# Spirit3 register map
File version: 1.0
CPU: CM0+ r0p0, little endian, no MPU, no FPU, 2 interrupt priority bits
Registers are 32-bit, read-write, reset 0x0 unless marked. A register's access mark holds for its fields unless they carry their own. Offsets are from the block's base; [hi:lo] are bit positions; {n}, {i} and the like mark numbered series.

## MR_SUBG
Base 0x49000000
0x00 RF_FSM0_TIMEOUT reset 0x14
  [7:0] ENA_RFREG_TIMER — Timeout for the RF regulator startup (duration in ENA_RF_REG state) Step = 16/CLK16M=1us
0x04 RF_FSM1_TIMEOUT reset 0x6
  [7:0] SYNTH_SETUP_TIMER — Timeout management for the RF regulator to stabilize after PLL power on Step = 16/CLK16M=1us
0x08 RF_FSM2_TIMEOUT reset 0x50
  [7:0] VCO_CALIB_LOCK_TIMER — Timeout for the PLL calibration + PLL lock (duration of CALIB_VCO+LOCKRXTX states) Step = 16/CLK16M=1us
0x0C RF_FSM3_TIMEOUT reset 0x28
  [7:0] VCO_LOCK_TIMER — Timeout for the PLL lock event when no calibration is requested (duration in LOCKRXTX state) Step = 16/CLK16M=1us
0x10 RF_FSM4_TIMEOUT reset 0xF
  [7:0] EN_RX_TIMER — Timeout for the analog RX chain setup with PGA precharge active (duration in EN_RX state) Step = 16/CLK16M=1us
0x14 RF_FSM5_TIMEOUT reset 0x19
  [7:0] EN_PA_TIMER — Timeout for the PA setup (duration in EN_PA state) Step = 16/CLK16M=1us
0x18 RF_FSM6_TIMEOUT reset 0x19
  [7:0] PA_DWN_ANA_TIMER — Timeout for the analog PA (DAC) ramp down (duration in PA_DWN_ANA state) Step = 16/CLK16M=1us
0x1C RF_FSM7_TIMEOUT reset 0x5
  [7:0] EN_LNA_TIMER — Timeout for RX chain last signals settlement once PGA precharge is shut down (duration in EN_LNA state)
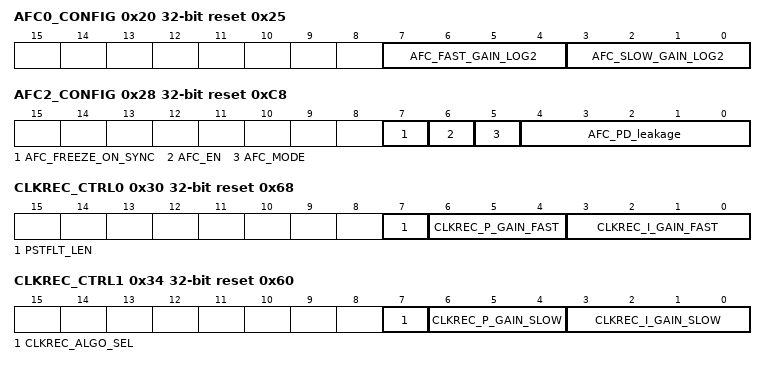
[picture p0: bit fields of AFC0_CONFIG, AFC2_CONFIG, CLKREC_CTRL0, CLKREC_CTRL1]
0x20 AFC0_CONFIG reset 0x25
  [7:4] AFC_FAST_GAIN_LOG2 — AFC loop gain in fast mode (2's log)
  [3:0] AFC_SLOW_GAIN_LOG2 — AFC loop gain in slow mode (2's log)
0x24 AFC1_CONFIG reset 0x18
  [7:0] AFC_FAST_PERIOD — Length of the AFC fast period (in number of samples unit)
0x28 AFC2_CONFIG reset 0xC8
  [7] AFC_FREEZE_ON_SYNC — Freeze the AFC correction upon SYNC word detection
  [6] AFC_EN — Enable AFC
  [5] AFC_MODE — Select AFC mode
  [4:0] AFC_PD_leakage — AFC Peak Detection leakage
0x2C AFC3_CONFIG
  [0] AFC_INIT_MODE — Control the initialization phase of the AGC and clock recovery algorithms
0x30 CLKREC_CTRL0 reset 0x68
  [7] PSTFLT_LEN — Control the length of the demodulator post-filter
  [6:4] CLKREC_P_GAIN_FAST — Clock recovery fast loop gain (log2)
  [3:0] CLKREC_I_GAIN_FAST — Integral fast gain for the clock recovery loop (PLL mode only)
0x34 CLKREC_CTRL1 reset 0x60
  [7] CLKREC_ALGO_SEL — Symbol timing recovery algorithm selection
  [6:4] CLKREC_P_GAIN_SLOW — Clock recovery slow loop gain (log2)
  [3:0] CLKREC_I_GAIN_SLOW — Integral slow gain for the clock recovery loop (PLL mode only)
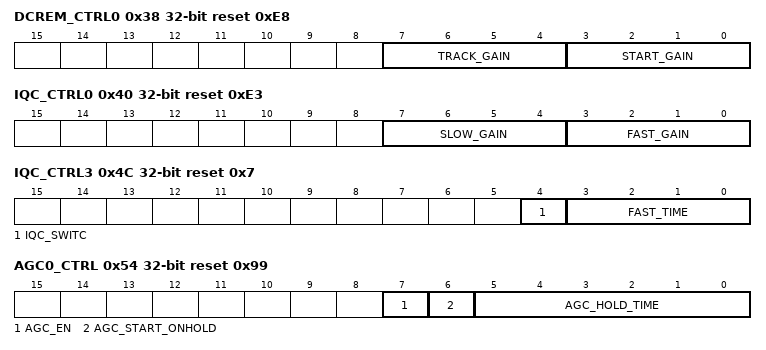
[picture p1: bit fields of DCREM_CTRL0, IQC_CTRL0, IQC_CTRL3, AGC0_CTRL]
0x38 DCREM_CTRL0 reset 0xE8
  [7:4] TRACK_GAIN — Filter gain in track mode for the DC removal block
  [3:0] START_GAIN — Filter gain in start mode for the DC removal block
0x3C DCREM_CTRL1 reset 0x5
  [3:0] LN2TIME2SET — Set the length of the start period for the DC removal block
0x40 IQC_CTRL0 reset 0xE3
  [7:4] SLOW_GAIN — Gain of the correction loop in slow mode
  [3:0] FAST_GAIN — Gain of the correction loop in fast mode
0x44 IQC_CTRL1 reset 0x8
  [7:0] QPD_ATTACK — Attack coefficient for QPD
0x48 IQC_CTRL2 reset 0x8
  [7:0] QPD_DECAY — Decay coefficient for QPD
0x4C IQC_CTRL3 reset 0x7
  [4] IQC_SWITC — (test and debug purpose only)
  [3:0] FAST_TIME — Duration of the fast mode
0x54 AGC0_CTRL reset 0x99
  [7] AGC_EN — Enable the AGC
  [6] AGC_START_ONHOLD — Start the AGC with a hold phase
  [5:0] AGC_HOLD_TIME
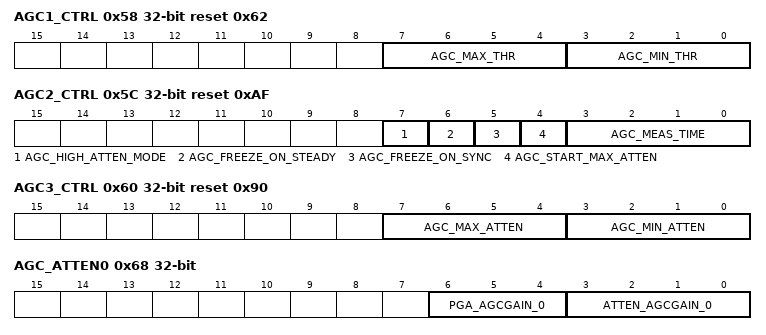
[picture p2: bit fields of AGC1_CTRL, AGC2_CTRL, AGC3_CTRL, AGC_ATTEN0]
0x58 AGC1_CTRL reset 0x62
  [7:4] AGC_MAX_THR — Maximum signal threshold
  [3:0] AGC_MIN_THR — Minimum signal threshold
0x5C AGC2_CTRL reset 0xAF
  [7] AGC_HIGH_ATTEN_MODE — Enable the high attenuation mode
  [6] AGC_FREEZE_ON_STEADY — Enable the autofreeze feature
  [5] AGC_FREEZE_ON_SYNC — Enable the freeze on SYNC detection feature
  [4] AGC_START_MAX_ATTEN — Start the AGC with maximum attenuation
  [3:0] AGC_MEAS_TIME — Measure time
0x60 AGC3_CTRL reset 0x90
  [7:4] AGC_MAX_ATTEN — Maximum AGC attenuation
  [3:0] AGC_MIN_ATTEN — Minimum AGC attenuation
0x64 AGC4_CTRL reset 0x2
  [3:0] AGC_FREEZE_THR — Signal threshold for the autofreeze feature
0x68 AGC_ATTEN0
  [6:4] PGA_AGCGAIN_0 — AGC attenuation control setting for step 0 on PGA point
  [3:0] ATTEN_AGCGAIN_0 — AGC attenuation control setting for step 0 for LNA+BOM point
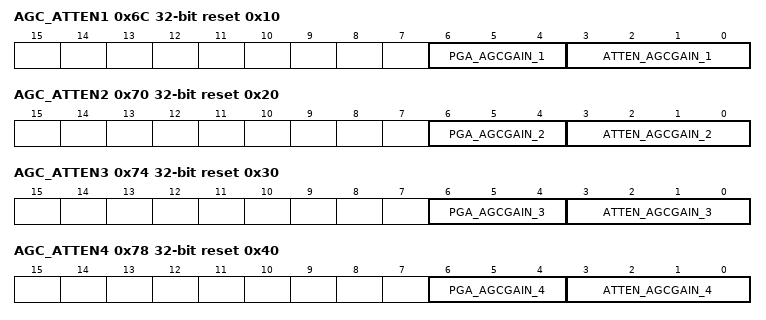
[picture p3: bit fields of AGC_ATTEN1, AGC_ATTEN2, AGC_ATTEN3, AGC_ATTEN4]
0x6C AGC_ATTEN1 reset 0x10
  [6:4] PGA_AGCGAIN_1 — AGC attenuation control setting for step 1 on PGA point
  [3:0] ATTEN_AGCGAIN_1 — AGC attenuation control setting for step 1 for LNA+BOM point
0x70 AGC_ATTEN2 reset 0x20
  [6:4] PGA_AGCGAIN_2 — AGC attenuation control setting for step 2 on PGA point
  [3:0] ATTEN_AGCGAIN_2 — AGC attenuation control setting for step 2 for LNA+BOM point
0x74 AGC_ATTEN3 reset 0x30
  [6:4] PGA_AGCGAIN_3 — AGC attenuation control setting for step 3 on PGA point
  [3:0] ATTEN_AGCGAIN_3 — AGC attenuation control setting for step 3 for LNA+BOM point
0x78 AGC_ATTEN4 reset 0x40
  [6:4] PGA_AGCGAIN_4 — AGC attenuation control setting for step 4 on PGA point
  [3:0] ATTEN_AGCGAIN_4 — AGC attenuation control setting for step 4 for LNA+BOM point
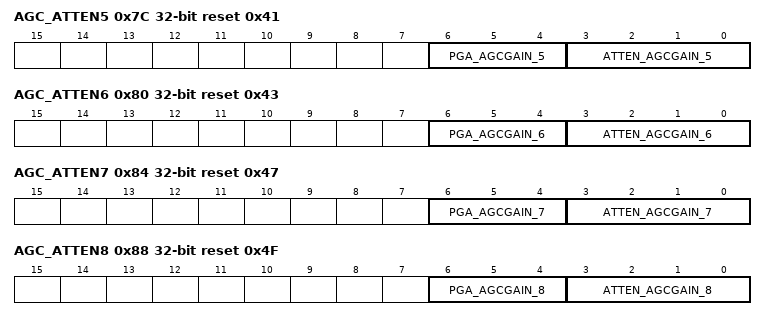
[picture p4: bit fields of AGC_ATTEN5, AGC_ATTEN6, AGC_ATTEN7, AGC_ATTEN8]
0x7C AGC_ATTEN5 reset 0x41
  [6:4] PGA_AGCGAIN_5 — AGC attenuation control setting for step 5 on PGA point
  [3:0] ATTEN_AGCGAIN_5 — AGC attenuation control setting for step 5 for LNA+BOM point
0x80 AGC_ATTEN6 reset 0x43
  [6:4] PGA_AGCGAIN_6 — AGC attenuation control setting for step 6 on PGA point
  [3:0] ATTEN_AGCGAIN_6 — AGC attenuation control setting for step 6 for LNA+BOM point
0x84 AGC_ATTEN7 reset 0x47
  [6:4] PGA_AGCGAIN_7 — AGC attenuation control setting for step 7 on PGA point
  [3:0] ATTEN_AGCGAIN_7 — AGC attenuation control setting for step 7 for LNA+BOM point
0x88 AGC_ATTEN8 reset 0x4F
  [6:4] PGA_AGCGAIN_8 — AGC attenuation control setting for step 8 on PGA point
  [3:0] ATTEN_AGCGAIN_8 — AGC attenuation control setting for step 8 for LNA+BOM point
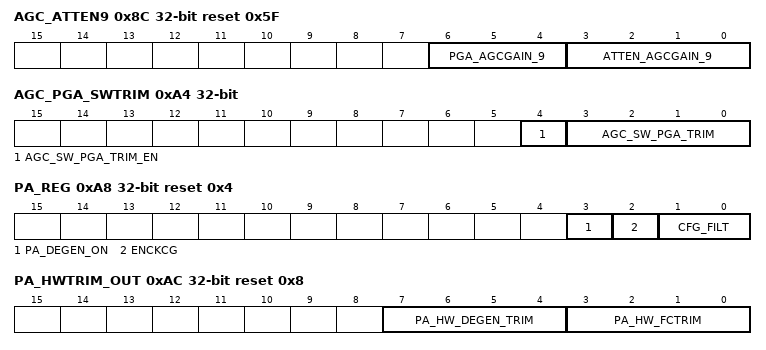
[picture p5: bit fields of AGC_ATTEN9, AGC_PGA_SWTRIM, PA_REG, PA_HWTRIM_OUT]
0x8C AGC_ATTEN9 reset 0x5F
  [6:4] PGA_AGCGAIN_9 — AGC attenuation control setting for step 9 on PGA point
  [3:0] ATTEN_AGCGAIN_9 — AGC attenuation control setting for step 9 for LNA+BOM point
{0x8C+4i} AGC{i}_ATTEN_TRIM reset 0xAF (i=1..4)
  [7:0] AGC{i}_ATTEN_TRIM_IN — AGC ATTEN trim[7:0] (calibration in) for step{i} on AGC_ATTEN
0xA0 AGC_PGA_HWTRIM_OUT ro reset 0x8
  [3:0] AGC_HW_PGA_TRIM — AGC PGA calibration information loaded by HW from the SoC flash (OBL section)
0xA4 AGC_PGA_SWTRIM
  [4] AGC_SW_PGA_TRIM_EN — Enable overload of PGA HW trim by a SW value
  [3:0] AGC_SW_PGA_TRIM — AGC PGA calibration information provided by SW
0xA8 PA_REG reset 0x4
  [3] PA_DEGEN_ON — Enable a 'degeneration' mode, which introduces a pre-distortion to linearize the power control curve
  [2] ENCKCG — FIR clock gating
  [1:0] CFG_FILT — FIR configuration
0xAC PA_HWTRIM_OUT ro reset 0x8
  [7:4] PA_HW_DEGEN_TRIM — MSB part meaning
  [3:0] PA_HW_FCTRIM — PA FC trimming information loaded by HW
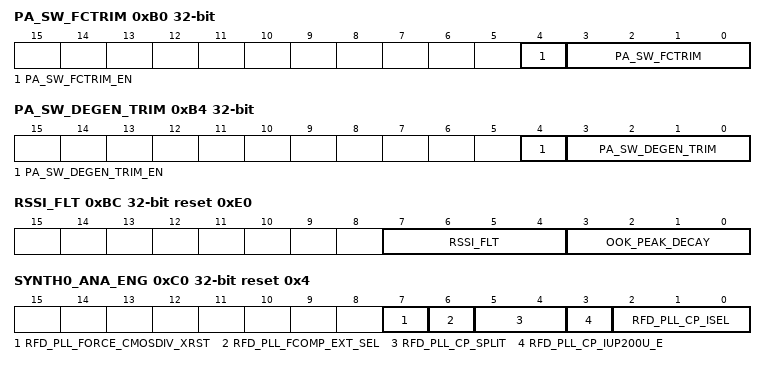
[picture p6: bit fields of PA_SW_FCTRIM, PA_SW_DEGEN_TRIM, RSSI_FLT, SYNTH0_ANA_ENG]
0xB0 PA_SW_FCTRIM
  [4] PA_SW_FCTRIM_EN — Enable overload of PA FC HW trim by a SW value
  [3:0] PA_SW_FCTRIM — PA FC trimming information provided by SW
0xB4 PA_SW_DEGEN_TRIM
  [4] PA_SW_DEGEN_TRIM_EN — Enable overload of PA DEGEN HW trim by a SW value
  [3:0] PA_SW_DEGEN_TRIM — PA DEGEN trimming information provided by SW
0xBC RSSI_FLT reset 0xE0
  [7:4] RSSI_FLT — Gain of the RSSI filter
  [3:0] OOK_PEAK_DECAY — Peak decay control for OOK
0xC0 SYNTH0_ANA_ENG reset 0x4
  [7] RFD_PLL_FORCE_CMOSDIV_XRST — For debug
  [6] RFD_PLL_FCOMP_EXT_SEL — For debug
  [5:4] RFD_PLL_CP_SPLIT — Change CP comparator current capability (for debug)
  [3] RFD_PLL_CP_IUP200U_E — For debug
  [2:0] RFD_PLL_CP_ISEL — Change Charge Pump biasing current configuration (for debug) default value is centered value = 3'b100
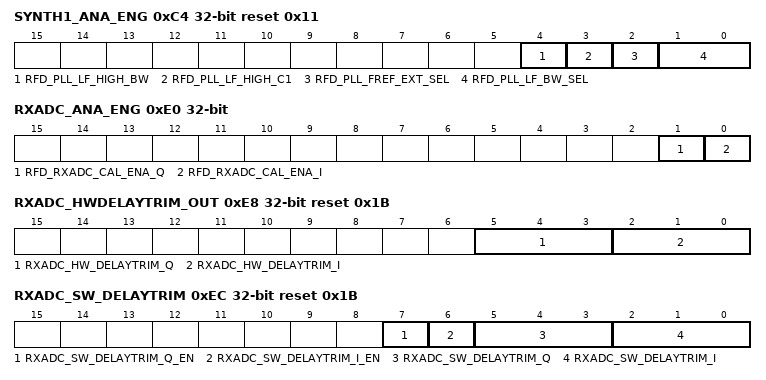
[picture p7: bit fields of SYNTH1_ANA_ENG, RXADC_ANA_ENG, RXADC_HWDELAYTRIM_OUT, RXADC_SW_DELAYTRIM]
0xC4 SYNTH1_ANA_ENG reset 0x11
  [4] RFD_PLL_LF_HIGH_BW — Double Resistor’s filter value (for debug) Default value (normal mode) is1
  [3] RFD_PLL_LF_HIGH_C1 — For debug. PLL-Loop Filter setting (=1 select the maximum value of C1 in loop filter)
  [2] RFD_PLL_FREF_EXT_SEL — For debug
  [1:0] RFD_PLL_LF_BW_SEL — Resistor filter’s bandwidth adjustment (for debug) Default value (normal mode) is 01
0xC8 SYNTH2_ANA_ENG reset 0x4
  [2:0] RFD_PLL_VCO_ALC_AMP — Select the level of max VCO amplitude in amplitude level control loop
0xD4 SYNTHCAL_DIG_ENG
  [7:0] PLL_RFCOUNTER_OFFSET — Control offset of PLL_RFCOUNTER output
0xE0 RXADC_ANA_ENG
  [1] RFD_RXADC_CAL_ENA_Q — Enable calibration on RX_ADC Q channel
  [0] RFD_RXADC_CAL_ENA_I — Enable calibration on RX_ADC I channel
0xE8 RXADC_HWDELAYTRIM_OUT ro reset 0x1B
  [5:3] RXADC_HW_DELAYTRIM_Q — Control bits of the RX ADC loop delay for Q channel
  [2:0] RXADC_HW_DELAYTRIM_I — Control bits of the RX ADC loop delay for I channel
0xEC RXADC_SW_DELAYTRIM reset 0x1B
  [7] RXADC_SW_DELAYTRIM_Q_EN — Select the SW trim instead of the HW trimmings
  [6] RXADC_SW_DELAYTRIM_I_EN — Select the SW trim instead of the HW trimmings
  [5:3] RXADC_SW_DELAYTRIM_Q — Control bits of the RX ADC loop delay for Q channel, provided by SW
  [2:0] RXADC_SW_DELAYTRIM_I — Control bits of the RX ADC loop delay for I channel, provided by SW
0xF4 RX_AAF_HWTRIM_OUT ro reset 0x6
  [3:0] AAF_HW_FCTRIM — AAF calibration information loaded by HW
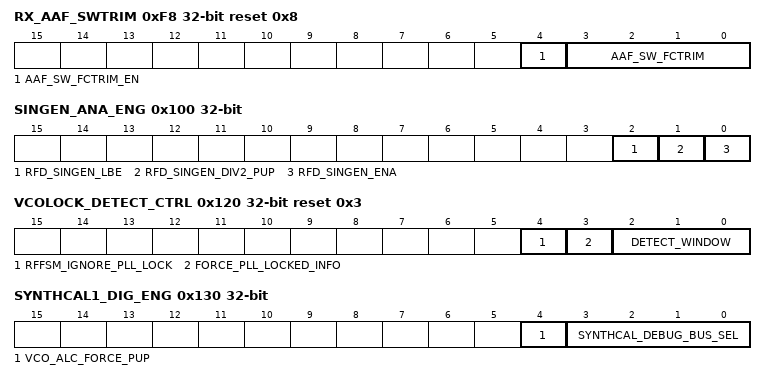
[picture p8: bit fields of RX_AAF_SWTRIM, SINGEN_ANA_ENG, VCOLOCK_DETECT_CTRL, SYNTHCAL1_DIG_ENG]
0xF8 RX_AAF_SWTRIM reset 0x8
  [4] AAF_SW_FCTRIM_EN — Select AAF_SW_TRIM[3:0] instead of AAF_HW_TRIM[3:0] info to provide to AAF analog block as calibration value
  [3:0] AAF_SW_FCTRIM — AAF calibration information to provide by SW (supposed to be the result of the AAF calibration, stored in a non-volatile memory)
0x100 SINGEN_ANA_ENG
  [2] RFD_SINGEN_LBE — This bit value is directly connected to the RFSUBG analog IP pin
  [1] RFD_SINGEN_DIV2_PUP — This bit value is directly connected to the RFSUBG analog IP pin
  [0] RFD_SINGEN_ENA — Enable SINGEN signal for the RFSUBG analog IP
0x104 RFANA_SPARE_IN_ENG
  [7:0] RFANA_SPARE_IN — Spare bits entering directly the RFSUBG analog IP
0x108 RFANA_SPARE_OUT ro
  [7:0] RFANA_SPARE_OUT — Spare bits coming directly from the RFSUBG analog IP
0x10C RFANA_PLL_SPARE_IN reset 0x80
  [7:4] RFANA_PLL_SPARE_IN — Spare bits entering directly the RFSUBG analog IP
0x120 VCOLOCK_DETECT_CTRL reset 0x3
  [4] RFFSM_IGNORE_PLL_LOCK — (debug and test) Information for the Radio FSM to go on sequence despite PLL is not locked
  [3] FORCE_PLL_LOCKED_INFO — (debug and test) Disable the PLL lock detection and force the PLL lock information high (for debug and test purposes) digital block
  [2:0] DETECT_WINDOW — Define integration window width for lock detection
0x124 RF_FSM8_TIMEOUT reset 0xA
  [7:0] SYNTH_PDWN_TIMER — Timeout management for the RF regulator to stabilize after PLL shut down
0x128 RF_FSM9_TIMEOUT reset 0x6
  [7:0] END_RX_TIMER — Timeout management for the RF regulator to stabilize after analog RX chain shut down
0x12C RF_FSM10_TIMEOUT reset 0x6
  [7:0] END_TX_TIMER — Timeout management for the RF regulator to stabilize after clock stop on the analog PA
0x130 SYNTHCAL1_DIG_ENG
  [4] VCO_ALC_FORCE_PUP — Force the enable of the Analog Amplitude Level Control on VCO (debug and test only)
  [3:0] SYNTHCAL_DEBUG_BUS_SEL — Select what is visible in DEBUG_BUS[7:0] in SYNTHCAL_DIG_OUT register
0x138 SYNTHCAL_DIG_OUT ro
  [7:0] SYNTHCAL_DEBUG_BUS — VCO calibration debug bus
0x140 DTB_CONFIG
  [5:0] DTB_CONFIG — DTB configuration selection.
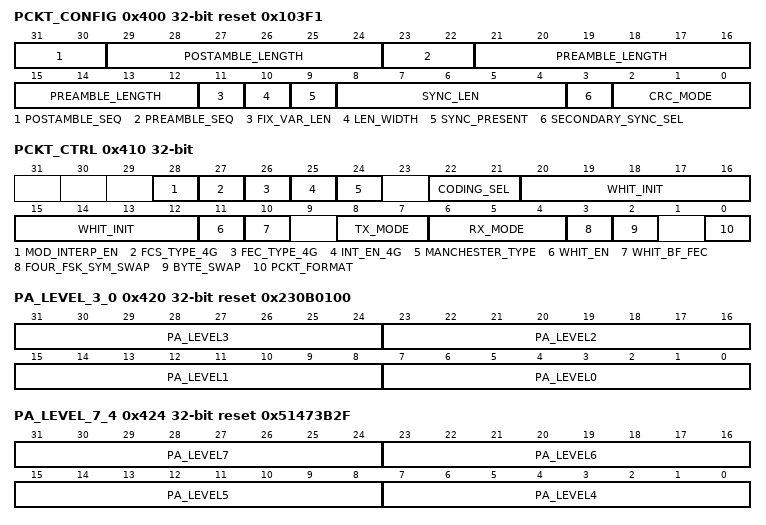
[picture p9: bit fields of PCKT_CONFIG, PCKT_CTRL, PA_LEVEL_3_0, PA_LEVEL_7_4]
0x400 PCKT_CONFIG reset 0x103F1
  [31:30] POSTAMBLE_SEQ — Packet postamble control: postamble bit sequence selection
  [29:24] POSTAMBLE_LENGTH — Length of the POSTAMBLE in pair of bits (0 to 126 bits)
  [23:22] PREAMBLE_SEQ — Select the PREAMBLE pattern to be applied
  [21:12] PREAMBLE_LENGTH — Length of the PREAMBLE in pairs of bits (0 to 2046 bits)
  [11] FIX_VAR_LEN — Select the length mode
  [10] LEN_WIDTH — Indicates if the LENGTH field is defined on 1 byte or 2 bytes
  [9] SYNC_PRESENT — Indicate if a SYNC word is present on the frame or not (null length)
  [8:4] SYNC_LEN — Length of the SYNC (and secondary) SYNC word in 1-bit granularity
  [3] SECONDARY_SYNC_SEL — In TX mode: this bit selects which synchro word is sent on the frame between SYNC and SEC_SYNC
  [2:0] CRC_MODE — CRC type (0, 8, 16, 16 802.15.4 compatible, 24, 32 bits)
0x404 SYNC reset 0x23232323
  [31:0] SYNC — Synchro word
0x408 SEC_SYNC
  [31:0] SEC_SYNC — Secondary Synchro word
0x40C CRC_INIT
  [31:0] CRC_INIT_VAL — CRC initialization value
0x410 PCKT_CTRL
  [28] MOD_INTERP_EN — Enable frequency interpolator (for 2-GFSK and 4-GFSK)
  [27] FCS_TYPE_4G — FCS type value in header field for 802.15.4g
  [26] FEC_TYPE_4G — FEC type for 802.15.4g
  [25] INT_EN_4G — This field is used as Interleaving enable for 802.15.4g
  [24] MANCHESTER_TYPE — Change the Manchester encoding polarity
  [22:21] CODING_SEL — Coding / decoding selection
  [20:12] WHIT_INIT — Whitening initialization value
  [11] WHIT_EN — Whitening enable
  [10] WHIT_BF_FEC — Whitening before FEC feature
  [8:7] TX_MODE
  [6:4] RX_MODE
  [3] FOUR_FSK_SYM_SWAP — Invert bit to symbol mapping for 4(G)FSK
  [2] BYTE_SWAP — (feature for Basic Packet format only)
  [0] PCKT_FORMAT — Packet format
0x414 DATABUFFER0_PTR
  [31:2] DATABUFFER0_PTR — Start address to be used by the Data Buffer0
0x418 DATABUFFER1_PTR
  [31:2] DATABUFFER1_PTR — Start address to be used by the Data Buffer1
0x41C DATABUFFER_SIZE
  [15:0] DATABUFFER_SIZE — Size of the Data Buffers (Data Buffer0 and Data Buffer1) expressed in byte unit
0x420 PA_LEVEL_3_0 reset 0x230B0100
  [31:24] PA_LEVEL3 — Output power level for fourth step (Max - 23 dB)
  [23:16] PA_LEVEL2 — Output power level for third step (Max - 35 dB)
  [15:8] PA_LEVEL1 — Output power level for second step (Max - 40 dB)
  [7:0] PA_LEVEL0 — Output power level for first step (no output power)
0x424 PA_LEVEL_7_4 reset 0x51473B2F
  [31:24] PA_LEVEL7 — Output power level for eighth step (Max up to 16 or 20dBm depending on the BOM)
  [23:16] PA_LEVEL6 — Output power level for seventh step (default is Max - 5 dB)
  [15:8] PA_LEVEL5 — Output power level for sixth step (default Max - 11 dB)
  [7:0] PA_LEVEL4 — Output power level for fifth step ((Max - 17 dB)
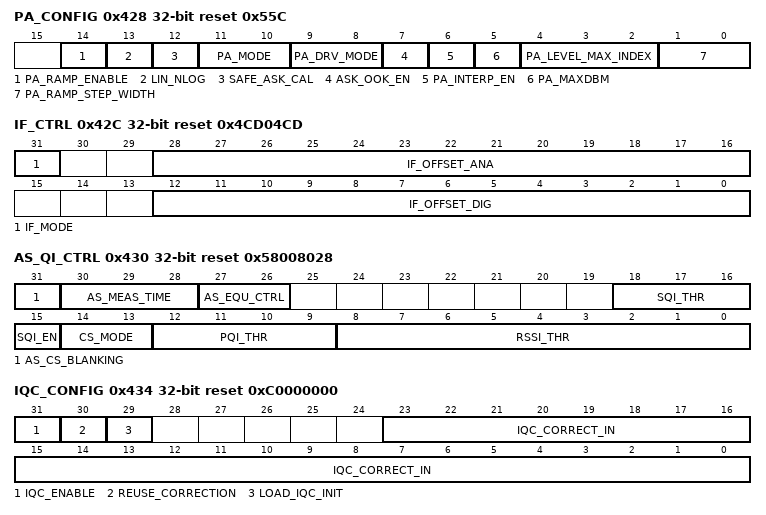
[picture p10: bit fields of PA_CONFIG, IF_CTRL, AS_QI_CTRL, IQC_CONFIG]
0x428 PA_CONFIG reset 0x55C
  [14] PA_RAMP_ENABLE — - When PA_M add a delay of 1 symbol before to stop the TX (to manage a ramp-down if last bit issued is a ‘1’)
  [13] LIN_NLOG — Enable/disable the linear-to-log conversion of the PA code output from the Safe-ASK calibrator
  [12] SAFE_ASK_CAL — During a TX operation, enables and starts the digital ASK calibrator (managed by Radio FSM, additional option versus dedicated command)
  [11:10] PA_MODE — Configure the Power Amplifier (PA) mode: - 00: SPIRIT1 'legacy' mode
  [9:8] PA_DRV_MODE — Request to use the high-power PA output (to reach the +20dBm target)
  [7] ASK_OOK_EN — Enable the generation of the internal signal TXDATA which is the input of the FIR (8 taps), enabled by same bit (otherwise FIR is excluded, output fixed at level '1')
  [6] PA_INTERP_EN — Enable power level interpolator
  [5] PA_MAXDBM — Configure the Power Amplifier (PA) output power
  [4:2] PA_LEVEL_MAX_INDEX — Final level for power up ramping
  [1:0] PA_RAMP_STEP_WIDTH — Step width (unit: 1/8 of bit period)
0x42C IF_CTRL reset 0x4CD04CD
  [31] IF_MODE — Select the cutoff frequency of the AAF information for the analog RFSUBG IP): - 0 (default): FC=684kHz (for IF=300kHz)
  [28:16] IF_OFFSET_ANA — Intermediate frequency setting for the synthesizer configuration (default: 300 kHz)
  [12:0] IF_OFFSET_DIG — Intermediate frequency setting for the digital shift-to-baseband circuits (default: 300 kHz)
0x430 AS_QI_CTRL reset 0x58008028
  [31] AS_CS_BLANKING — Blank received data if signal is below the CS threshold
  [30:28] AS_MEAS_TIME — Antenna switching measurement time
  [27:26] AS_EQU_CTRL — ISI cancellation equalizer: - 00: equalization disabled
  [18:16] SQI_THR — SQI threshold defining the precision requested to detect the SYNC word
  [15] SQI_EN — SQI enable
  [14:13] CS_MODE — Carrier Sense mode selection
  [12:9] PQI_THR — PQI threshold (if 0 then PQI is disabled)
  [8:0] RSSI_THR — Signal detect threshold in 1 dB resolution
0x434 IQC_CONFIG reset 0xC0000000
  [31] IQC_ENABLE — Enable IQC
  [30] REUSE_CORRECTION — Reuse last correction value
  [29] LOAD_IQC_INIT — Action bit to load the IQC_CORRECT_IN[23:0] bit field in the recirculation register when this bit is written to 1
  [23:0] IQC_CORRECT_IN — Correction value Input for the IQ compensation engine (to be used as starting point or when the engine is disabled)
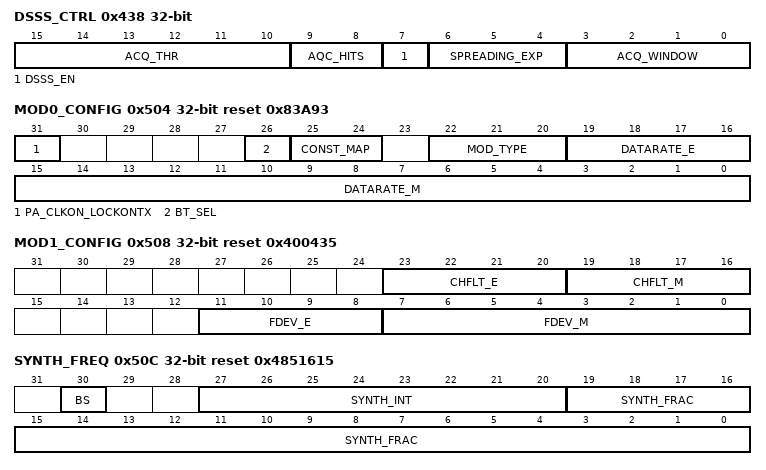
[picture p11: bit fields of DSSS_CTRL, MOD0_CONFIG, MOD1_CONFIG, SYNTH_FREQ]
0x438 DSSS_CTRL
  [15:10] ACQ_THR — DSSS acquisition threshold
  [9:8] AQC_HITS — DSSS acquisition hits
  [7] DSSS_EN — DSSS mode enable
  [6:4] SPREADING_EXP — DSSS spreading exponent
  [3:0] ACQ_WINDOW — DSSS Acquisition window
0x500 PCKTLEN_CONFIG reset 0x14
  [15:0] PCKTLEN — This bit field has different meaning/usag
0x504 MOD0_CONFIG reset 0x83A93
  [31] PA_CLKON_LOCKONTX — Enable the clock on analog PA in LOCKONTX state
  [26] BT_SEL — Select BT value for GFSK
  [25:24] CONST_MAP — 2- and 4-(G)FSK constellation mapping. See Table 5 and Table 6 to see the associated mapping
  [22:20] MOD_TYPE — Modulation type
  [19:16] DATARATE_E — The exponent of the specified data rate (default: 38.4 ksps)
  [15:0] DATARATE_M — The Mantissa of the specified data rate (default: 38.4 ksps)
0x508 MOD1_CONFIG reset 0x400435
  [23:20] CHFLT_E — Exponent of the channel filter BW (default: 100 kHz)
  [19:16] CHFLT_M — Mantissa of the channel filter BW (default: 100 kHz)
  [11:8] FDEV_E — Exponent of the frequency deviation (default: 20 kHz)
  [7:0] FDEV_M — Mantissa of the frequency deviation (default: 20 kHz)
0x50C SYNTH_FREQ reset 0x4851615
  [30] BS — Synthesizer band selector, i.e. out-of-loop total divide factor, 4 or 8
  [27:20] SYNTH_INT — PLL integer divide factor (default: 868 MHz, XTAL: 48 MHz)
  [19:0] SYNTH_FRAC — Fractional part of the PLL fractional divide factor (default: 868 MHz, XTAL: 48 MHz)
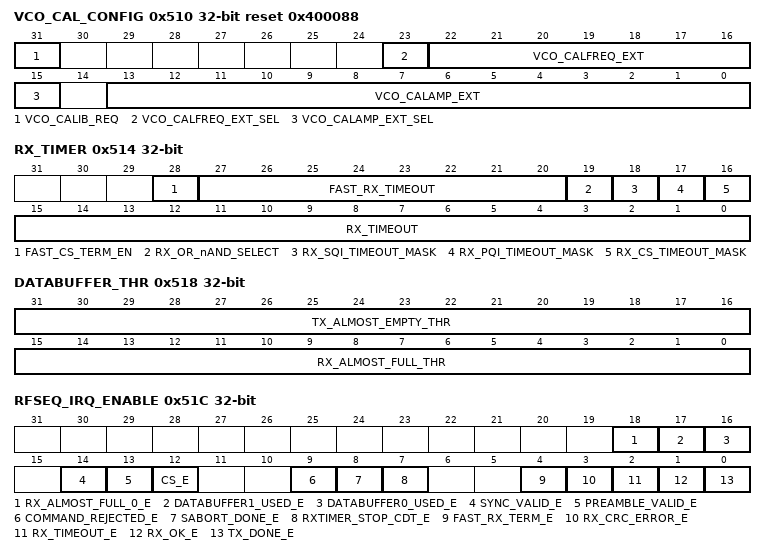
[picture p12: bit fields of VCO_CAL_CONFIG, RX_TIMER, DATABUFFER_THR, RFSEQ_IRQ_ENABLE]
0x510 VCO_CAL_CONFIG reset 0x400088
  [31] VCO_CALIB_REQ — Define if the Radio FSM must launch a VCO calibration request after VCO start-up
  [23] VCO_CALFREQ_EXT_SEL — Select the mode to provide an external VCO frequency calibration value through VCO_CALFREQ_EXT bit field: - 0: the VCO frequency calibration value generated by the VCO calibration block is applied to the VCO
  [22:16] VCO_CALFREQ_EXT — VCO Cbank frequency calibration word
  [15] VCO_CALAMP_EXT_SEL — Select the mode to provide an external VCO amplitude calibration value through VCO_CALAMP_EXT bit field: - 0: the VCO amplitude calibration value generated by the VCO calibration block is applied to the VCO
  [13:0] VCO_CALAMP_EXT — VCO magnitude calibration word in thermometric code
0x514 RX_TIMER
  [28] FAST_CS_TERM_EN — Enable the Fast Rx Termination mode
  [27:20] FAST_RX_TIMEOUT — Fast RX Termination timer value
  [19] RX_OR_nAND_SELECT — Select logical OR or logical AND to apply on CS/PQI/SQI timeout mask: - 0: AND is applied
  [18] RX_SQI_TIMEOUT_MASK — - 0: SQI valid flag does not contribute to timeout disabling
  [17] RX_PQI_TIMEOUT_MASK — - 0: PREAMBLE valid flag does not contribute to timeout disabling
  [16] RX_CS_TIMEOUT_MASK — - 0: CS flag does not contribute to timeout disabling
  [15:0] RX_TIMEOUT — RX timer timeout (relative duration in interpolated absolute time unit)
0x518 DATABUFFER_THR
  [31:16] TX_ALMOST_EMPTY_THR — Almost Empty threshold for TX Data Buffers
  [15:0] RX_ALMOST_FULL_THR — Almost Full threshold for RX Data Buffers
0x51C RFSEQ_IRQ_ENABLE
  [18] RX_ALMOST_FULL_0_E — Enable interrupt on RX_ALMOST_FULL_0_F flag
  [17] DATABUFFER1_USED_E — Enable interrupt on DATABUFFER1_USED_F flag
  [16] DATABUFFER0_USED_E — Enable interrupt on DATABUFFER0_USED_F flag
  [14] SYNC_VALID_E — Enable interrupt on SYNC_VALIF_F flag
  [13] PREAMBLE_VALID_E — Enable interrupt on PREAMBLE_VALIF_F flag
  [12] CS_E — Enable interrupt on CS_F flag
  [9] COMMAND_REJECTED_E — Enable interrupt on COMMAND_REJECTED flag
  [8] SABORT_DONE_E — Enable interrupt on SABORT command treated and done flag
  [7] RXTIMER_STOP_CDT_E — Enable interrupt on RXTIMER_STOP_CDT_F flag
  [4] FAST_RX_TERM_E — Enable interrupt on FAST_RX_TERM_F flag
  [3] RX_CRC_ERROR_E — Enable interrupt on RX_CRC_ERROR_F flag
  [2] RX_TIMEOUT_E — Enable interrupt on RX_TIMEOUT_F flag
  [1] RX_OK_E — Enable interrupt on RX_OK_F flag
  [0] TX_DONE_E — Enable interrupt on TX_DONE_F flag
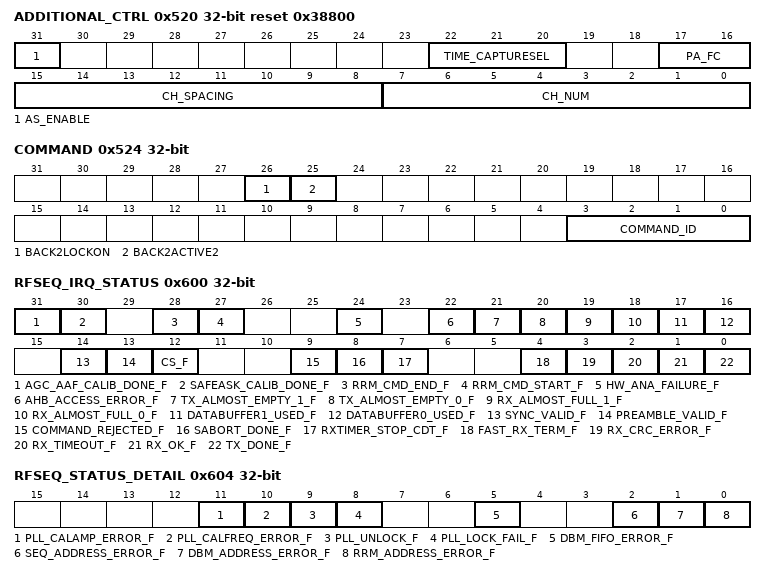
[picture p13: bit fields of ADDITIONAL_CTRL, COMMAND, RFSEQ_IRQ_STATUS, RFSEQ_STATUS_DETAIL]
0x520 ADDITIONAL_CTRL reset 0x38800
  [31] AS_ENABLE — Enable the antenna switching feature
  [22:20] TIME_CAPTURESEL — Select the trigger event that captures the interpolated absolute time in the TIME_CAPTURE[31:0] register
  [17:16] PA_FC — Power control bandwidth selection according data rate (for ASK/OOK modulation)
  [15:8] CH_SPACING — Channel spacing. From ~732 Hz to ~187 kHz in 732 Hz steps - default: 100 kHz
  [7:0] CH_NUM — Channel number
0x524 COMMAND
  [26] BACK2LOCKON — Target/return state for the Radio FSM when exiting a RX or a TX state is LOCKON
  [25] BACK2ACTIVE2 — Default/return state for the Radio FSM is ACTIVE2
  [3:0] COMMAND_ID — Opcode corresponding to a command
0x600 RFSEQ_IRQ_STATUS
  [31] AGC_AAF_CALIB_DONE_F — Valid RSSI value available in the RSSI_RUNNING bit field flag
  [30] SAFEASK_CALIB_DONE_F — End of Safe-ASK PA calibration flag
  [28] RRM_CMD_END_F — RRM-UDRA command list execution ended flag
  [27] RRM_CMD_START_F — RRM-UDRA command list execution started flag
  [24] HW_ANA_FAILURE_F — Analog HW failure flag (PLL lock / unlock error, calibration error)
  [22] AHB_ACCESS_ERROR_F — An AHB transfer issue occurred for one of the AHB masters (RRM, Data Buffer Manager, Sequencer). Details are available in the annex register called RFSEQ_STATUS_DETAIL
  [21] TX_ALMOST_EMPTY_1_F — Data Buffer 1 read by the HW up to programmed threshold flag
  [20] TX_ALMOST_EMPTY_0_F — Data Buffer 0 read by the HW up to programmed threshold flag
  [19] RX_ALMOST_FULL_1_F — Data Buffer 1 written by the HW up to programmed threshold flag
  [18] RX_ALMOST_FULL_0_F — Data Buffer 0 written by the HW up to programmed threshold flag
  [17] DATABUFFER1_USED_F — Data Buffer 1 fully read in TX or fully written in RX flag
  [16] DATABUFFER0_USED_F — Data Buffer 0 fully read in TX or fully written in RX flag
  [14] SYNC_VALID_F — Valid SYNC word detection flag
  [13] PREAMBLE_VALID_F — Valid Preamble detection flag
  [12] CS_F — Carrier Sense (RSSI over threshold) flag
  [9] COMMAND_REJECTED_F — Command rejection flag
  [8] SABORT_DONE_F — SABORT command treated and done flag
  [7] RXTIMER_STOP_CDT_F — RX Timer stopped due to match with stop condition flag
  [4] FAST_RX_TERM_F — Fast RX Termination flag
  [3] RX_CRC_ERROR_F — Reception with CRC error flag
  [2] RX_TIMEOUT_F — Reception timeout flag
  [1] RX_OK_F — Reception ended and OK flag
  [0] TX_DONE_F — Transmission done flag
0x604 RFSEQ_STATUS_DETAIL
  [11] PLL_CALAMP_ERROR_F — VCO amplitude calibration error flag
  [10] PLL_CALFREQ_ERROR_F — VCO frequency calibration error flag
  [9] PLL_UNLOCK_F — PLL unlock event flag
  [8] PLL_LOCK_FAIL_F — PLL lock fail status flag
  [5] DBM_FIFO_ERROR_F — Data Buffer Manager internal FIFO overflow/underflow flag
  [2] SEQ_ADDRESS_ERROR_F — Sequencer AHB master tried to access to an unmapped RAM address
  [1] DBM_ADDRESS_ERROR_F — Data Buffer Manager AHB master tried to access to an unmapped RAM address
  [0] RRM_ADDRESS_ERROR_F — RRM AHB master tried to access to an unmapped RAM address
0x608 RADIO_FSM_INFO ro
  [4:0] RADIO_FSM_STATE — State of the Radio FSM
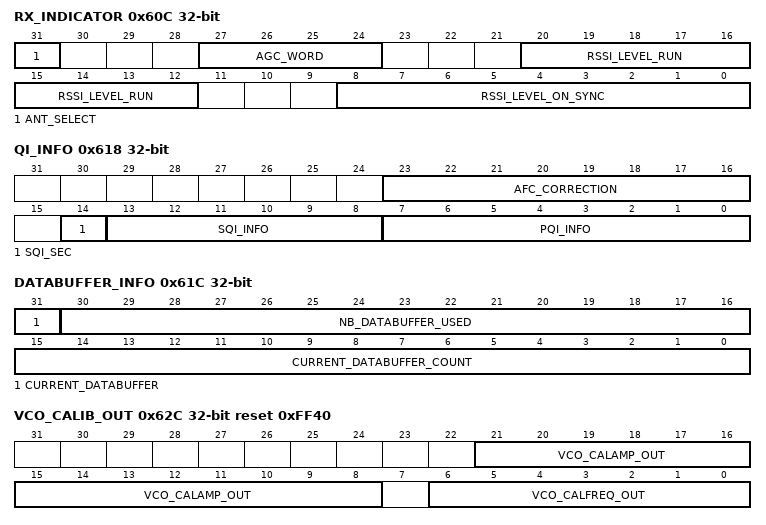
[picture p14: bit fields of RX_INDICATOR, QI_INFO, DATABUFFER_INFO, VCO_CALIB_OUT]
0x60C RX_INDICATOR ro
  [31] ANT_SELECT — Currently selected antenna
  [27:24] AGC_WORD — AGC word of the received packet
  [20:12] RSSI_LEVEL_RUN — Continuous level of the output of the measured RSSI value
  [8:0] RSSI_LEVEL_ON_SYNC — RSSI level captured at the end of the SYNC word detection of the received packet
0x610 RX_INFO_REG ro
  [15:0] RX_PCKTLEN_OUT — Indicates the received packet length in bytes
0x614 RX_CRC_REG ro
  [31:0] RX_CRC_OUT — CRC field of the received packet (read-only info)
0x618 QI_INFO ro
  [23:16] AFC_CORRECTION — AFC value frozen at sync reception
  [14] SQI_SEC — Indicate if measured SQI refers to SYNC word or secondary SYNC word
  [13:8] SQI_INFO — SYNC Quality Indicator (SQI) value of the received packet. Represents the peak value between 0 and 32
  [7:0] PQI_INFO — Preamble Quality Indicator (PQI) value of the received packet
0x61C DATABUFFER_INFO ro
  [31] CURRENT_DATABUFFER — Indicates which Data Buffer is currently used by the HW: - 0 = Data Buffer0
  [30:16] NB_DATABUFFER_USED — Provides the number of data buffers which have been fully used: - written during RX
  [15:0] CURRENT_DATABUFFER_COUNT — Indicates the number of bytes used in the last DATA BUFFER used
0x620 TIME_CAPTURE ro
  [31:0] TIME_CAPTURE — Interpolated absolute time (ABSOLUTE_TIME[31:0]) value captured on specific programmable event (tbd) through TIME_CAPTURESEL[2:0] bit field
0x624 IQC_CORRECTION_OUT ro
  [23:0] IQC_CORRECT_OUT — Final correction value output from IQC (compensation engine)
0x628 PA_SAFEASK_OUT ro
  [7:0] PA_CODEMAX — Safe ASK level (provided after a CALIB_SAFEASK command)
0x62C VCO_CALIB_OUT ro reset 0xFF40
  [21:8] VCO_CALAMP_OUT — VCO Amplitude Calibration value currently output by the VCO calibration block (applied on the VCO)
  [6:0] VCO_CALFREQ_OUT — VCO Frequency Calibration value currently output by the VCO calibration block(applied to the VCO)
0x700 RFIP_VERSION ro reset 0x1100
  [15:12] PRODUCT — Used for major upgrades (new protocols support / new features)
  [11:8] VERSION — Version of the MR_SubG (to be used for cut upgrades)
  [7:4] REVISION — Revision of the MR_SubG (to be used for metal fixes)
0x704 RRM_UDRA_CTRL wo
  [0] RRM_CMD_REQ — Action bit write 1 to request a RRM-UDRA command
0x708 SEQUENCER_CTRL
  [1] DISABLE_SEQ — Enable/disable the Sequencer
  [0] GEN_SEQ_TRIGGER — Action bit: write 1 to generate a trigger event on Sequencer
0x70C ABSOLUTE_TIME ro
  [31:0] ABSOLUTE_TIME — Indicate the interpolated absolute time
0x710 SCM_COUNTER_VAL ro
  [14:0] SCM_COUNTER_CURRVAL — Slow Clock Measurement: number of 16 MHz clock cycles contained in 32 slow clock periods
0x714 SCM_MIN_MAX reset 0x7FFF
  [31] CLEAR_MIN_MAX — Write ‘1’ to clear the SLOWCLK_MIN_VALUE and SLOWCLK_MAX_VALUE registers
  [30:16] SCM_COUNTER_MAXVAL — Slow Clock Measurement: maximum SCM_COUNTER value seen since the counter is ON and since last clear request
  [14:0] SCM_COUNTER_MINVAL — Slow Clock Measurement: minimum SCM_COUNTER value seen since the counter is ON and since last clear request
0x718 WAKEUP_IRQ_STATUS
  [1] RFIP_WAKEUP_F — Set when the interpolated absolute time matches the RFIP_WAKEUPTIME while WAKEUP_CTRL.RFIP_WAKEUP_EN=1
  [0] CPU_WAKEUP_F — Set when the interpolated absolute time matches the CPU_WAKEUPTIME while WAKEUP_CTRL.CPU_WAKEUP_EN=1
0x780 RFIP_WAKEUPTIME ro
  [31:0] RFIP_WAKEUPTIME — Target time to wake up the RFIP
0x784 CPU_WAKEUPTIME
  [31:0] CPU_WAKEUPTIME — Target time to wake up the CPU
0x788 WAKEUP_CTRL
  [31] RFIP_WAKEUP_EN — Indicates if the wakeup timer has to wake up the SoC
  [30] CPU_WAKEUP_EN — Indicates if the wakeup timer has to wake up the SoC
  [7:0] SOC_WAKEUP_OFFSET — Delay to be considered by the Wakeup block to anticipate the wakeup req to the PWRC of the SoC versus the target to wake up the RFIP
0x78C RRM_CMDLIST_PTR
  [31] CMDLIST_PTR_VALID — Indicate if a command list can be executed or not
  [15:0] CMDLIST_PTR_OFFSET — Contain the offset versus the SoC RAM base address where to find the RRM-UDRA command list entry point
0x790 SEQ_GLOBALTABLE_PTR
  [15:0] SEQ_GLOBALTABLE_PTR — Contain the offset versus the RAM base address of the GlobalConfiguration RAM table entry point used by the Sequencer
